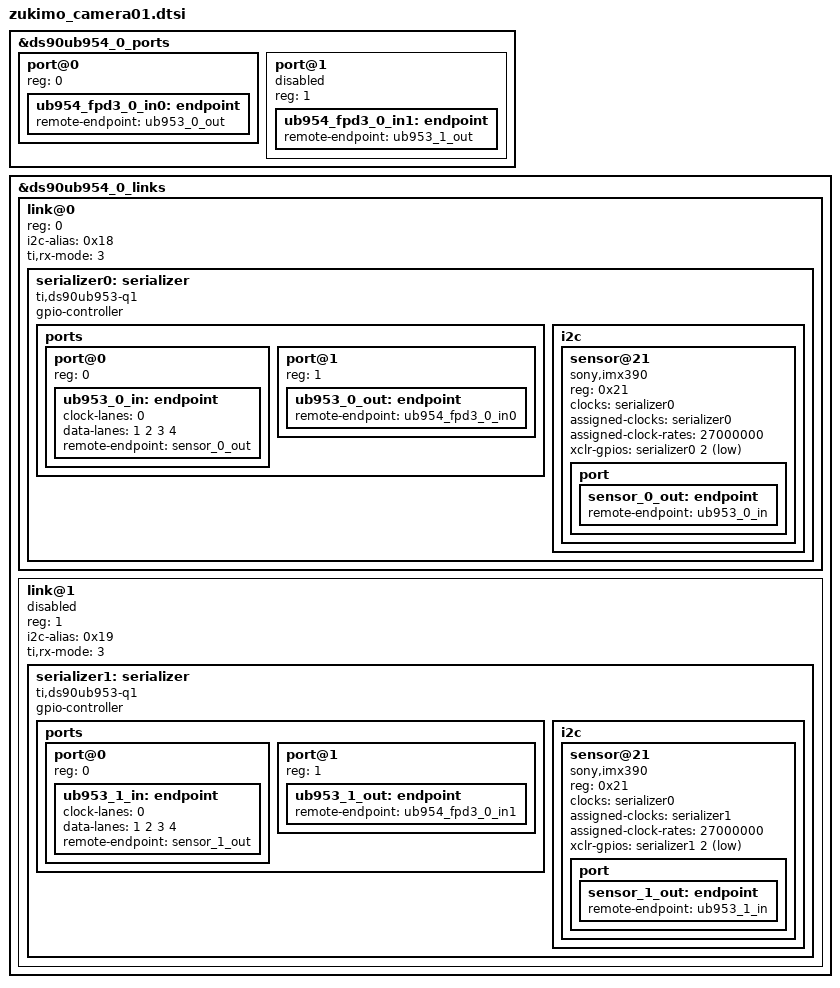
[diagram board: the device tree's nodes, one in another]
// SPDX-License-Identifier: GPL-2.0

#include <dt-bindings/gpio/gpio.h>

&ds90ub954_0_ports {
	#address-cells = <1>;
	#size-cells = <0>;

	/* FPDLink RX 1 */
	port@0 {
		reg = <0>;

		ub954_fpd3_0_in0: endpoint {
			remote-endpoint = <&ub953_0_out>;
		};
	};
	/* FPDLink RX 2 */
	port@1 {
		reg = <1>;

		status = "disabled";

		ub954_fpd3_0_in1: endpoint {
			remote-endpoint = <&ub953_1_out>;
		};
	};
};

&ds90ub954_0_links {
	#address-cells = <1>;
	#size-cells = <0>;

	link@0 {
		reg = <0>;
		i2c-alias = <0x18>;
		ti,rx-mode = <3>;

		serializer0: serializer {
			compatible = "ti,ds90ub953-q1";
			gpio-controller;
			#gpio-cells = <2>;

			#clock-cells = <0>;

			ports {
				#address-cells = <1>;
				#size-cells = <0>;

				port@0 {
					reg = <0>;
					ub953_0_in: endpoint {
						clock-lanes = <0>;
						data-lanes = <1 2 3 4>;
						remote-endpoint = <&sensor_0_out>;
					};
				};

				port@1 {
					reg = <1>;

					ub953_0_out: endpoint {
						remote-endpoint = <&ub954_fpd3_0_in0>;
					};
				};
			};

			i2c {
				#address-cells = <1>;
				#size-cells = <0>;

				sensor@21 {
					compatible = "sony,imx390";
					reg = <0x21>;

					clocks = <&serializer0>;
					clock-names = "inck";
					assigned-clocks = <&serializer0>;
					assigned-clock-rates = <27000000>;

					xclr-gpios = <&serializer0 2 GPIO_ACTIVE_LOW>;

					port {
						sensor_0_out: endpoint {
							remote-endpoint = <&ub953_0_in>;
						};
					};
				};
			};
		};
	};

	link@1 {
		reg = <1>;
		i2c-alias = <0x19>;
		ti,rx-mode = <3>;

		status = "disabled";
		
		serializer1: serializer {
			compatible = "ti,ds90ub953-q1";
			gpio-controller;
			#gpio-cells = <2>;

			#clock-cells = <0>;

			ports {
				#address-cells = <1>;
				#size-cells = <0>;

				port@0 {
					reg = <0>;
					ub953_1_in: endpoint {
						clock-lanes = <0>;
						data-lanes = <1 2 3 4>;
						remote-endpoint = <&sensor_1_out>;
					};
				};

				port@1 {
					reg = <1>;

					ub953_1_out: endpoint {
						remote-endpoint = <&ub954_fpd3_0_in1>;
					};
				};
			};

			i2c {
				#address-cells = <1>;
				#size-cells = <0>;

				sensor@21 {
					compatible = "sony,imx390";
					reg = <0x21>;

					clocks = <&serializer0>;
					clock-names = "inck";
					assigned-clocks = <&serializer1>;
					assigned-clock-rates = <27000000>;

					xclr-gpios = <&serializer1 2 GPIO_ACTIVE_LOW>;

					port {
						sensor_1_out: endpoint {
							remote-endpoint = <&ub953_1_in>;
						};
					};
				};
			};
		};
	};
};
